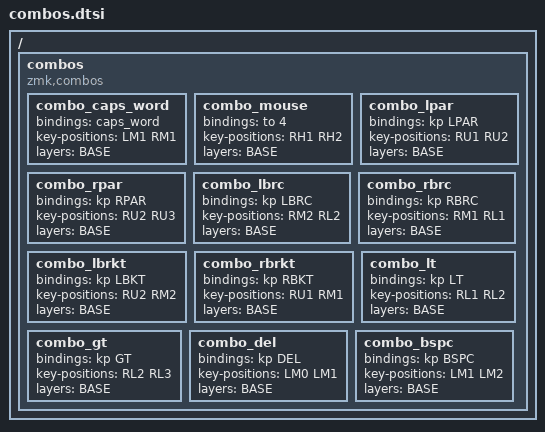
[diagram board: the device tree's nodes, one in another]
/ {

    combos {
        compatible = "zmk,combos";

        combo_caps_word {
            bindings = <&caps_word>;
            key-positions = <LM1 RM1>;
            layers = <BASE>;
        };

        combo_mouse {
            bindings = <&to 4>;
            key-positions = <RH1 RH2>;
            layers = <BASE>;
        };

        // combo_equal {
        //     bindings = <&kp EQUAL>;
        //     key-positions = <RM0 RM1>;
        //     layers = <BASE>;
        // };

        combo_lpar {
            bindings = <&kp LPAR>;
            key-positions = <RU1 RU2>;
            layers = <BASE>;
        };

        combo_rpar {
            bindings = <&kp RPAR>;
            key-positions = <RU2 RU3>;
            layers = <BASE>;
        };

        combo_lbrc {
            bindings = <&kp LBRC>;
            key-positions = <RM2 RL2>;
            layers = <BASE>;
        };

        combo_rbrc {
            bindings = <&kp RBRC>;
            key-positions = <RM1 RL1>;
            layers = <BASE>;
        };

        combo_lbrkt {
            bindings = <&kp LBKT>;
            key-positions = <RU2 RM2>;
            layers = <BASE>;
        };

        combo_rbrkt {
            bindings = <&kp RBKT>;
            key-positions = <RU1 RM1>;
            layers = <BASE>;
        };

        combo_lt {
            bindings = <&kp LT>;
            key-positions = <RL1 RL2>;
            layers = <BASE>;
        };

        combo_gt {
            bindings = <&kp GT>;
            key-positions = <RL2 RL3>;
            layers = <BASE>;
        };

        combo_del {
            bindings = <&kp DEL>;
            key-positions = <LM0 LM1>;
            layers = <BASE>;
        };

        combo_bspc {
            bindings = <&kp BSPC>;
            key-positions = <LM1 LM2>;
            layers = <BASE>;
        };

    };
};
